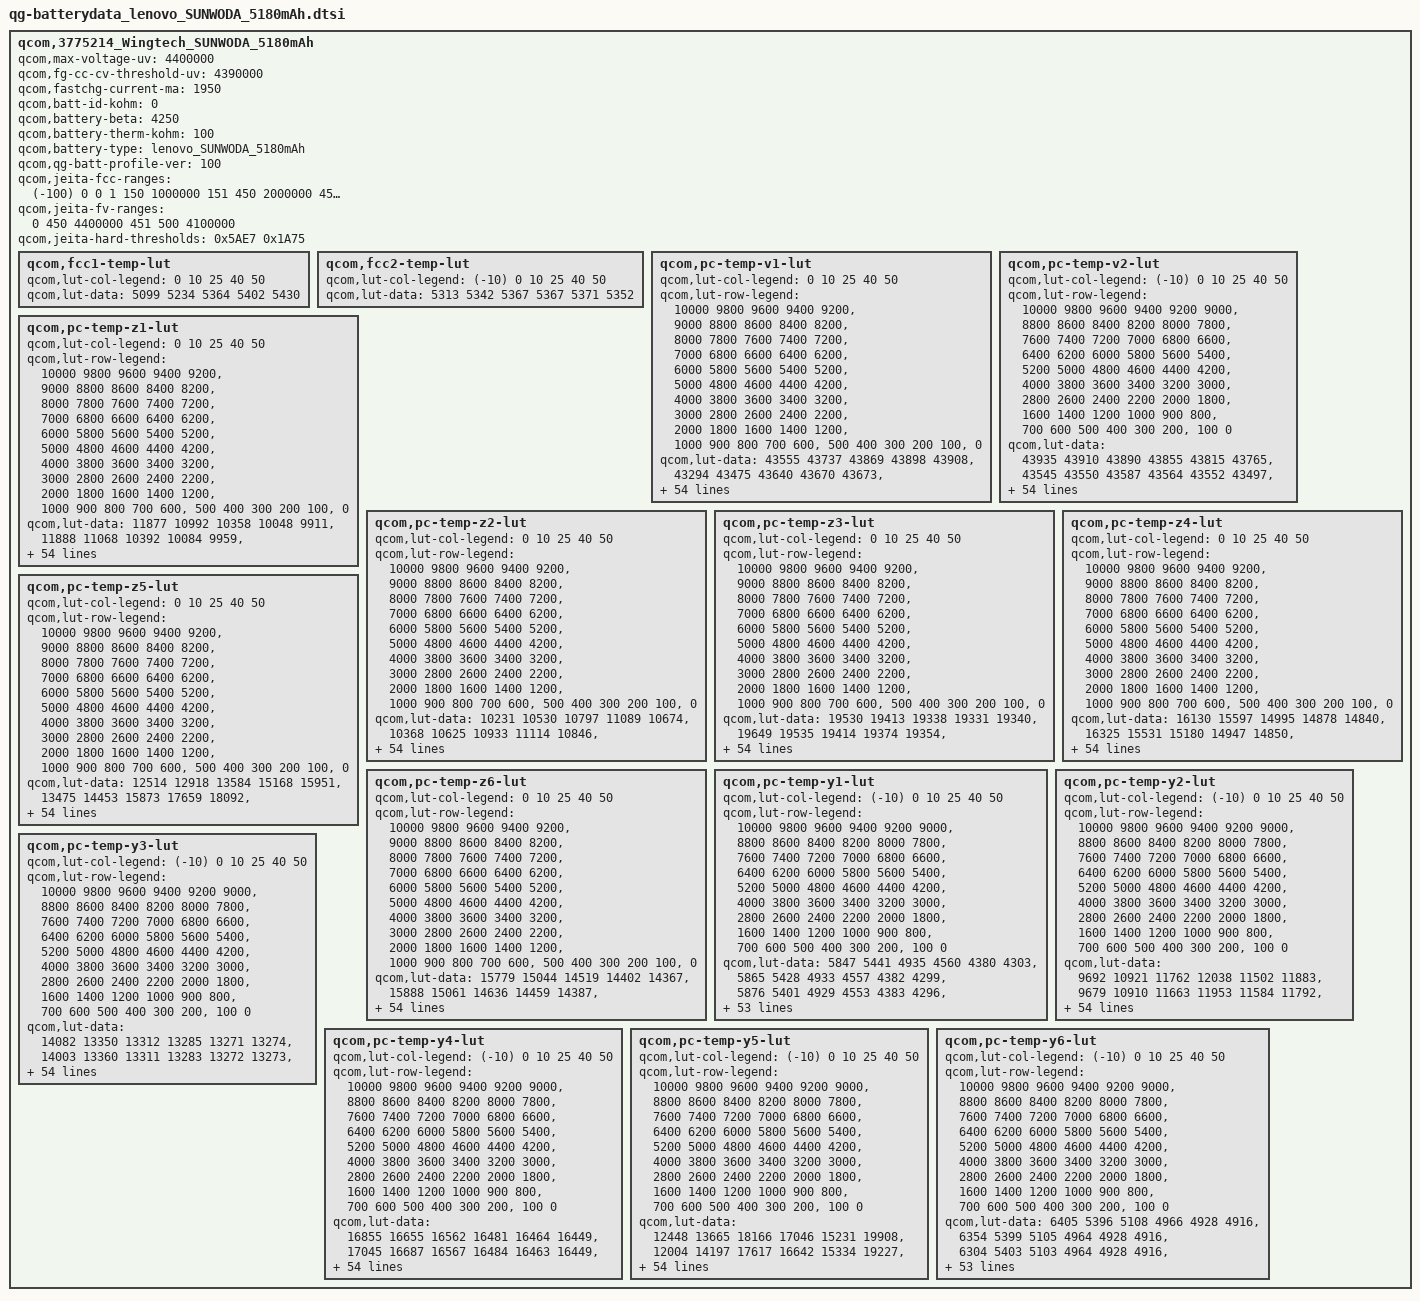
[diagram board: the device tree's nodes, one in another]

qcom,3775214_Wingtech_SUNWODA_5180mAh {
    /* 3775214_Wingtech_3677A4lenovo_5300mAh_averaged_MasterSlave_Nov30th2018 */
    qcom,max-voltage-uv = <4400000>;
    qcom,fg-cc-cv-threshold-uv = <4390000>;
    qcom,fastchg-current-ma = <1950>;
    qcom,batt-id-kohm = <0>;
    qcom,battery-beta = <4250>;
    qcom,battery-therm-kohm = <100>;
    qcom,battery-type = "lenovo_SUNWODA_5180mAh";
    qcom,qg-batt-profile-ver = <100>;
    qcom,jeita-fcc-ranges = <(-100) 0 0
                       1 150 1000000
                       151 450 2000000
		       451 500 1200000
			501 510 0>;
    qcom,jeita-fv-ranges = <0 450 4400000
                       451 500 4100000>;
    qcom,jeita-hard-thresholds = <0x5AE7 0x1A75>;

	qcom,fcc1-temp-lut {
		qcom,lut-col-legend = <0 10 25 40 50>;
		qcom,lut-data = <5099 5234 5364 5402 5430>;
	};

	qcom,fcc2-temp-lut {
		qcom,lut-col-legend = <(-10) 0 10 25 40 50>;
		qcom,lut-data = <5313 5342 5367 5367 5371 5352>;
	};

	qcom,pc-temp-v1-lut {
		qcom,lut-col-legend = <0 10 25 40 50>;
		qcom,lut-row-legend = <10000 9800 9600 9400 9200>,
			<9000 8800 8600 8400 8200>,
			<8000 7800 7600 7400 7200>,
			<7000 6800 6600 6400 6200>,
			<6000 5800 5600 5400 5200>,
			<5000 4800 4600 4400 4200>,
			<4000 3800 3600 3400 3200>,
			<3000 2800 2600 2400 2200>,
			<2000 1800 1600 1400 1200>,
			<1000 900 800 700 600>,
			<500 400 300 200 100>,
			<0>;
		qcom,lut-data = <43555 43737 43869 43898 43908>,
			<43294 43475 43640 43670 43673>,
			<43039 43220 43397 43440 43442>,
			<42791 42974 43152 43210 43214>,
			<42550 42733 42908 42974 42982>,
			<42316 42494 42663 42732 42743>,
			<42089 42260 42421 42491 42503>,
			<41872 42031 42180 42250 42263>,
			<41663 41809 41944 42011 42024>,
			<41460 41593 41711 41776 41789>,
			<41268 41390 41485 41545 41558>,
			<41070 41203 41272 41319 41331>,
			<40852 41004 41077 41097 41107>,
			<40622 40759 40870 40880 40889>,
			<40388 40494 40619 40667 40678>,
			<40130 40265 40364 40461 40474>,
			<39904 40061 40168 40267 40279>,
			<39760 39887 40011 40086 40093>,
			<39651 39756 39860 39912 39915>,
			<39541 39646 39714 39753 39749>,
			<39424 39519 39565 39597 39593>,
			<39307 39371 39381 39397 39407>,
			<39190 39211 39162 39114 39150>,
			<39071 39029 38955 38879 38913>,
			<38960 38832 38751 38750 38768>,
			<38858 38675 38582 38652 38658>,
			<38762 38546 38496 38552 38551>,
			<38673 38446 38441 38452 38446>,
			<38588 38379 38386 38361 38350>,
			<38510 38329 38325 38280 38263>,
			<38445 38287 38266 38208 38185>,
			<38385 38250 38211 38144 38116>,
			<38333 38217 38160 38089 38056>,
			<38285 38185 38112 38037 37999>,
			<38241 38158 38072 37990 37948>,
			<38199 38127 38032 37944 37899>,
			<38159 38095 37995 37897 37846>,
			<38117 38058 37956 37850 37791>,
			<38070 38003 37902 37789 37725>,
			<38015 37921 37815 37706 37642>,
			<37937 37824 37710 37607 37544>,
			<37809 37708 37600 37499 37433>,
			<37669 37572 37474 37373 37304>,
			<37522 37410 37317 37216 37150>,
			<37368 37265 37171 37069 37010>,
			<37255 37165 37078 36999 36922>,
			<37217 37142 37049 36959 36899>,
			<37185 37115 37036 36951 36881>,
			<37157 37095 37017 36929 36865>,
			<37119 37066 36989 36895 36830>,
			<36986 36926 36830 36707 36621>,
			<36584 36514 36422 36301 36205>,
			<36025 35958 35868 35750 35647>,
			<35268 35199 35109 34975 34886>,
			<34081 34021 33942 33802 33719>,
			<30000 30000 30000 30000 30000>;
	};

	qcom,pc-temp-v2-lut {
		qcom,lut-col-legend = <(-10) 0 10 25 40 50>;
		qcom,lut-row-legend = <10000 9800 9600 9400 9200 9000>,
			<8800 8600 8400 8200 8000 7800>,
			<7600 7400 7200 7000 6800 6600>,
			<6400 6200 6000 5800 5600 5400>,
			<5200 5000 4800 4600 4400 4200>,
			<4000 3800 3600 3400 3200 3000>,
			<2800 2600 2400 2200 2000 1800>,
			<1600 1400 1200 1000 900 800>,
			<700 600 500 400 300 200>,
			<100 0>;
		qcom,lut-data = <43935 43910 43890 43855 43815 43765>,
			<43545 43550 43587 43564 43552 43497>,
			<43184 43219 43300 43288 43295 43238>,
			<42851 42924 43028 43027 43047 42987>,
			<42539 42660 42772 42782 42805 42746>,
			<42269 42406 42524 42541 42566 42507>,
			<42060 42153 42280 42301 42326 42269>,
			<41871 41908 42042 42063 42088 42031>,
			<41631 41664 41811 41829 41854 41798>,
			<41327 41417 41584 41598 41623 41566>,
			<41108 41206 41363 41371 41395 41339>,
			<41027 41058 41158 41148 41171 41116>,
			<40961 40913 40946 40930 40951 40898>,
			<40735 40677 40666 40724 40739 40688>,
			<40120 40321 40316 40525 40532 40482>,
			<39638 40008 40022 40320 40332 40285>,
			<39458 39778 39789 40096 40136 40094>,
			<39326 39578 39576 39882 39948 39910>,
			<39165 39389 39364 39720 39773 39738>,
			<38985 39213 39160 39586 39608 39577>,
			<38814 39041 39029 39419 39422 39396>,
			<38656 38866 38923 39175 39196 39169>,
			<38512 38700 38821 38932 38974 38943>,
			<38396 38550 38708 38753 38789 38763>,
			<38297 38411 38561 38601 38625 38607>,
			<38214 38291 38434 38473 38490 38476>,
			<38145 38184 38328 38365 38382 38366>,
			<38085 38094 38230 38269 38285 38268>,
			<38029 38028 38140 38180 38195 38178>,
			<37978 37974 38056 38099 38111 38096>,
			<37930 37928 37980 38027 38037 38021>,
			<37883 37890 37909 37958 37967 37953>,
			<37838 37854 37850 37896 37907 37890>,
			<37790 37818 37807 37836 37860 37831>,
			<37742 37781 37772 37781 37816 37775>,
			<37690 37741 37736 37729 37752 37701>,
			<37634 37698 37703 37681 37650 37593>,
			<37574 37650 37664 37630 37551 37484>,
			<37510 37591 37614 37565 37472 37400>,
			<37442 37524 37552 37494 37398 37325>,
			<37372 37445 37477 37431 37319 37244>,
			<37298 37347 37381 37370 37234 37157>,
			<37221 37235 37261 37251 37137 37053>,
			<37138 37107 37119 37081 37014 36925>,
			<37048 36987 36989 36999 36856 36796>,
			<36948 36890 36898 36886 36817 36764>,
			<36890 36843 36878 36873 36808 36750>,
			<36828 36798 36857 36856 36792 36734>,
			<36750 36758 36810 36830 36771 36710>,
			<36631 36671 36757 36777 36726 36656>,
			<36456 36515 36568 36589 36541 36397>,
			<36110 36171 36166 36123 36037 35972>,
			<35579 35610 35572 35515 35463 35337>,
			<34781 34805 34747 34679 34648 34476>,
			<33550 33541 33509 33448 33304 33171>,
			<28789 28553 28733 29045 29438 29953>;
	};

	qcom,pc-temp-z1-lut {
		qcom,lut-col-legend = <0 10 25 40 50>;
		qcom,lut-row-legend = <10000 9800 9600 9400 9200>,
			<9000 8800 8600 8400 8200>,
			<8000 7800 7600 7400 7200>,
			<7000 6800 6600 6400 6200>,
			<6000 5800 5600 5400 5200>,
			<5000 4800 4600 4400 4200>,
			<4000 3800 3600 3400 3200>,
			<3000 2800 2600 2400 2200>,
			<2000 1800 1600 1400 1200>,
			<1000 900 800 700 600>,
			<500 400 300 200 100>,
			<0>;
		qcom,lut-data = <11877 10992 10358 10048 9911>,
			<11888 11068 10392 10084 9959>,
			<11908 11097 10392 10088 9959>,
			<11925 11077 10391 10091 9959>,
			<11937 11049 10388 10091 9959>,
			<11956 11047 10385 10089 9959>,
			<11963 11057 10383 10087 9958>,
			<11953 11064 10377 10084 9956>,
			<11937 11057 10373 10081 9954>,
			<11923 11048 10373 10081 9953>,
			<11901 11045 10374 10081 9955>,
			<11883 11044 10375 10081 9956>,
			<11877 11043 10382 10081 9956>,
			<11876 11035 10387 10080 9956>,
			<11873 11021 10376 10079 9957>,
			<11846 11019 10360 10076 9957>,
			<11821 11026 10358 10075 9958>,
			<11825 11033 10362 10077 9958>,
			<11840 11041 10366 10079 9958>,
			<11846 11053 10371 10080 9958>,
			<11840 11057 10376 10081 9959>,
			<11833 11057 10378 10082 9960>,
			<11839 11058 10379 10083 9961>,
			<11858 11057 10381 10084 9962>,
			<11873 11057 10387 10086 9964>,
			<11871 11060 10394 10090 9967>,
			<11864 11075 10396 10093 9970>,
			<11874 11090 10396 10095 9974>,
			<11916 11096 10397 10097 9976>,
			<11950 11101 10404 10101 9977>,
			<11945 11103 10413 10105 9977>,
			<11925 11099 10416 10106 9978>,
			<11917 11095 10418 10106 9980>,
			<11922 11100 10421 10107 9982>,
			<11932 11112 10425 10108 9984>,
			<11945 11123 10429 10111 9987>,
			<11965 11135 10435 10115 9988>,
			<11979 11146 10441 10122 9989>,
			<11992 11157 10446 10125 9991>,
			<12009 11170 10452 10126 9993>,
			<12005 11181 10458 10126 9996>,
			<11965 11188 10466 10127 9998>,
			<11950 11191 10473 10129 9999>,
			<11961 11192 10469 10131 10001>,
			<11936 11187 10472 10162 10003>,
			<11951 11149 10475 10153 10007>,
			<11964 11175 10476 10144 10002>,
			<11940 11151 10483 10141 10001>,
			<11944 11171 10479 10143 10005>,
			<11961 11184 10487 10146 10008>,
			<11927 11197 10486 10157 10011>,
			<11931 11187 10498 10240 10016>,
			<11946 11196 10523 10170 10022>,
			<11960 11226 10540 10179 10035>,
			<11960 11226 10540 10179 10035>,
			<11960 11226 10540 10179 10035>;
	};

	qcom,pc-temp-z2-lut {
		qcom,lut-col-legend = <0 10 25 40 50>;
		qcom,lut-row-legend = <10000 9800 9600 9400 9200>,
			<9000 8800 8600 8400 8200>,
			<8000 7800 7600 7400 7200>,
			<7000 6800 6600 6400 6200>,
			<6000 5800 5600 5400 5200>,
			<5000 4800 4600 4400 4200>,
			<4000 3800 3600 3400 3200>,
			<3000 2800 2600 2400 2200>,
			<2000 1800 1600 1400 1200>,
			<1000 900 800 700 600>,
			<500 400 300 200 100>,
			<0>;
		qcom,lut-data = <10231 10530 10797 11089 10674>,
			<10368 10625 10933 11114 10846>,
			<10428 10661 10897 11057 10978>,
			<10469 10639 10847 10967 10948>,
			<10495 10608 10781 10950 10927>,
			<10521 10610 10711 10948 10922>,
			<10530 10644 10703 10947 10916>,
			<10521 10665 10752 10962 10884>,
			<10508 10659 10799 10983 10841>,
			<10502 10646 10821 10986 10832>,
			<10491 10628 10837 10975 10845>,
			<10479 10597 10849 10968 10853>,
			<10456 10576 10863 10981 10863>,
			<10425 10575 10876 10997 10880>,
			<10403 10574 10893 11007 10869>,
			<10388 10576 10913 11016 10818>,
			<10376 10593 10928 11003 10793>,
			<10362 10619 10940 10963 10823>,
			<10347 10673 10958 10935 10858>,
			<10340 10751 11002 10944 10864>,
			<10340 10790 11058 10970 10862>,
			<10340 10808 11104 11011 10871>,
			<10340 10819 11147 11118 10935>,
			<10341 10831 11162 11190 10994>,
			<10342 10845 11091 11119 11012>,
			<10346 10848 11008 11000 11026>,
			<10353 10844 11012 11001 11021>,
			<10364 10839 11047 11120 10959>,
			<10384 10849 11077 11188 10907>,
			<10410 10878 11117 11112 10857>,
			<10436 10900 11150 11002 10787>,
			<10467 10911 11131 10961 10773>,
			<10497 10922 11074 10931 10768>,
			<10529 10935 11054 10929 10774>,
			<10562 10950 11071 11006 10794>,
			<10603 10965 11099 11113 10824>,
			<10654 10980 11136 11188 10867>,
			<10681 10996 11186 11255 10936>,
			<10486 11021 11226 11300 11003>,
			<10155 11057 11262 11369 11084>,
			<10104 11089 11289 11422 11151>,
			<10385 11115 11303 11390 11197>,
			<10423 11141 11316 11331 11254>,
			<9752 11169 11343 11331 11163>,
			<10006 11372 11384 11362 11073>,
			<10123 11570 11414 11891 11046>,
			<10193 12030 11442 11340 11090>,
			<10176 12151 11571 11924 11131>,
			<10563 12213 11676 11308 11176>,
			<10690 12427 11674 11403 11373>,
			<10414 12160 11870 11472 11152>,
			<11068 12001 11782 11338 10814>,
			<9981 12127 11760 12438 10707>,
			<9827 11598 11690 11139 10689>,
			<9827 11598 11690 11139 10689>,
			<9827 11598 11690 11139 10689>;
	};

	qcom,pc-temp-z3-lut {
		qcom,lut-col-legend = <0 10 25 40 50>;
		qcom,lut-row-legend = <10000 9800 9600 9400 9200>,
			<9000 8800 8600 8400 8200>,
			<8000 7800 7600 7400 7200>,
			<7000 6800 6600 6400 6200>,
			<6000 5800 5600 5400 5200>,
			<5000 4800 4600 4400 4200>,
			<4000 3800 3600 3400 3200>,
			<3000 2800 2600 2400 2200>,
			<2000 1800 1600 1400 1200>,
			<1000 900 800 700 600>,
			<500 400 300 200 100>,
			<0>;
		qcom,lut-data = <19530 19413 19338 19331 19340>,
			<19649 19535 19414 19374 19354>,
			<19695 19594 19456 19398 19383>,
			<19717 19606 19478 19410 19395>,
			<19712 19612 19481 19411 19397>,
			<19696 19609 19482 19404 19390>,
			<19687 19594 19480 19398 19383>,
			<19687 19578 19465 19393 19379>,
			<19687 19568 19449 19388 19375>,
			<19686 19559 19440 19383 19370>,
			<19684 19553 19432 19375 19363>,
			<19684 19547 19427 19370 19358>,
			<19692 19545 19423 19368 19355>,
			<19704 19548 19421 19366 19352>,
			<19707 19554 19421 19363 19348>,
			<19706 19552 19422 19358 19343>,
			<19704 19531 19417 19355 19339>,
			<19694 19506 19400 19351 19336>,
			<19669 19488 19390 19347 19334>,
			<19655 19474 19387 19343 19331>,
			<19651 19471 19386 19338 19327>,
			<19649 19482 19391 19338 19326>,
			<19650 19496 19411 19352 19331>,
			<19654 19509 19420 19362 19336>,
			<19657 19522 19416 19349 19331>,
			<19655 19525 19409 19328 19321>,
			<19651 19524 19401 19330 19322>,
			<19649 19523 19392 19362 19349>,
			<19651 19521 19388 19381 19370>,
			<19650 19518 19395 19381 19369>,
			<19643 19515 19403 19380 19365>,
			<19632 19511 19409 19378 19361>,
			<19622 19507 19414 19370 19354>,
			<19613 19501 19415 19364 19348>,
			<19604 19494 19411 19359 19342>,
			<19597 19488 19406 19354 19337>,
			<19591 19482 19401 19350 19333>,
			<19579 19476 19394 19346 19329>,
			<19499 19473 19391 19344 19327>,
			<19379 19471 19390 19343 19325>,
			<19354 19468 19389 19342 19325>,
			<19403 19460 19386 19340 19326>,
			<19409 19453 19383 19338 19330>,
			<19287 19448 19379 19338 19329>,
			<19264 19423 19372 19334 19326>,
			<19263 19395 19357 19301 19321>,
			<19262 19328 19358 19324 19314>,
			<19262 19324 19326 19296 19310>,
			<19260 19288 19327 19311 19307>,
			<19260 19285 19330 19309 19296>,
			<19262 19292 19315 19315 19311>,
			<19263 19293 19319 19311 19324>,
			<19263 19299 19313 19290 19322>,
			<19265 19297 19313 19310 19317>,
			<19265 19297 19313 19310 19317>,
			<19265 19297 19313 19310 19317>;
	};

	qcom,pc-temp-z4-lut {
		qcom,lut-col-legend = <0 10 25 40 50>;
		qcom,lut-row-legend = <10000 9800 9600 9400 9200>,
			<9000 8800 8600 8400 8200>,
			<8000 7800 7600 7400 7200>,
			<7000 6800 6600 6400 6200>,
			<6000 5800 5600 5400 5200>,
			<5000 4800 4600 4400 4200>,
			<4000 3800 3600 3400 3200>,
			<3000 2800 2600 2400 2200>,
			<2000 1800 1600 1400 1200>,
			<1000 900 800 700 600>,
			<500 400 300 200 100>,
			<0>;
		qcom,lut-data = <16130 15597 14995 14878 14840>,
			<16325 15531 15180 14947 14850>,
			<16183 15444 15080 14910 14856>,
			<15987 15317 14968 14840 14801>,
			<15828 15181 14900 14798 14766>,
			<15669 15093 14845 14767 14746>,
			<15534 15031 14812 14748 14733>,
			<15424 14978 14790 14739 14726>,
			<15328 14925 14775 14732 14722>,
			<15248 14879 14766 14726 14717>,
			<15179 14848 14759 14721 14712>,
			<15121 14825 14750 14715 14707>,
			<15067 14809 14739 14708 14701>,
			<15021 14801 14732 14701 14694>,
			<14996 14796 14731 14696 14688>,
			<14984 14791 14730 14691 14684>,
			<14973 14786 14726 14686 14679>,
			<14956 14781 14710 14677 14673>,
			<14934 14770 14698 14671 14667>,
			<14915 14755 14691 14669 14664>,
			<14897 14743 14688 14669 14661>,
			<14881 14732 14694 14680 14665>,
			<14868 14725 14724 14758 14735>,
			<14856 14742 14760 14817 14801>,
			<14848 14785 14815 14823 14805>,
			<14845 14814 14862 14826 14803>,
			<14843 14835 14860 14817 14793>,
			<14842 14847 14837 14766 14746>,
			<14836 14840 14813 14724 14706>,
			<14830 14820 14786 14707 14693>,
			<14827 14800 14760 14696 14684>,
			<14825 14783 14739 14688 14678>,
			<14822 14767 14721 14683 14673>,
			<14816 14753 14709 14680 14671>,
			<14808 14740 14702 14677 14671>,
			<14799 14729 14697 14676 14671>,
			<14784 14719 14693 14677 14673>,
			<14776 14712 14690 14680 14679>,
			<14844 14709 14691 14685 14686>,
			<14958 14707 14700 14693 14693>,
			<14979 14706 14709 14698 14699>,
			<14907 14707 14704 14695 14694>,
			<14890 14708 14696 14689 14685>,
			<15000 14705 14697 14692 14692>,
			<14946 14696 14689 14703 14692>,
			<14922 14697 14677 14701 14675>,
			<14916 14760 14666 14668 14670>,
			<14906 14756 14685 14676 14658>,
			<14900 14791 14671 14645 14639>,
			<14896 14788 14661 14640 14638>,
			<14897 14786 14695 14663 14657>,
			<14923 14807 14709 14712 14656>,
			<14938 14809 14719 14699 14660>,
			<14959 14823 14724 14686 14666>,
			<14959 14823 14724 14686 14666>,
			<14959 14823 14724 14686 14666>;
	};

	qcom,pc-temp-z5-lut {
		qcom,lut-col-legend = <0 10 25 40 50>;
		qcom,lut-row-legend = <10000 9800 9600 9400 9200>,
			<9000 8800 8600 8400 8200>,
			<8000 7800 7600 7400 7200>,
			<7000 6800 6600 6400 6200>,
			<6000 5800 5600 5400 5200>,
			<5000 4800 4600 4400 4200>,
			<4000 3800 3600 3400 3200>,
			<3000 2800 2600 2400 2200>,
			<2000 1800 1600 1400 1200>,
			<1000 900 800 700 600>,
			<500 400 300 200 100>,
			<0>;
		qcom,lut-data = <12514 12918 13584 15168 15951>,
			<13475 14453 15873 17659 18092>,
			<14172 15518 17152 19042 20392>,
			<14806 16161 18111 19914 21934>,
			<15481 16629 18958 20699 22751>,
			<16155 16977 19657 21469 23240>,
			<16777 17220 20121 21812 23513>,
			<17390 17523 20491 21982 23629>,
			<17999 18097 20676 22116 23654>,
			<18549 18817 20669 21953 23458>,
			<19049 19383 20642 21520 22744>,
			<19581 19802 20742 21339 22295>,
			<20322 20369 21279 21798 22682>,
			<21103 22041 21957 22398 23240>,
			<21466 24178 23160 22744 23245>,
			<21677 24398 24443 22953 22847>,
			<21795 22335 24337 22936 22729>,
			<21368 20578 23003 23453 23333>,
			<20216 20406 22268 24017 24183>,
			<19630 20585 23224 24070 24743>,
			<19875 21427 25448 24190 25218>,
			<20422 25866 31575 25588 25933>,
			<21154 32143 45733 32759 27652>,
			<22473 40213 52065 37717 28939>,
			<23477 49552 45490 30636 25448>,
			<23999 52152 35896 19158 17877>,
			<24461 49795 29791 17425 16131>,
			<24735 46689 24704 19898 19079>,
			<26293 44516 23084 22724 22405>,
			<27841 42567 23548 25380 24591>,
			<27965 40926 24482 27841 26477>,
			<27575 39456 26728 29219 27890>,
			<27322 38097 30970 30462 29078>,
			<26879 36806 33961 31695 30075>,
			<26117 35570 36599 33965 31135>,
			<25524 34820 38320 36036 31939>,
			<25468 34221 38125 35833 31668>,
			<24725 33773 37397 34311 30107>,
			<20227 34199 36741 32979 28269>,
			<14130 35818 35963 30587 25590>,
			<12898 36590 34929 27944 23513>,
			<15444 33348 33329 26376 23831>,
			<16049 30394 31252 25200 24702>,
			<12262 30245 28921 24474 23613>,
			<12237 28027 28642 23339 22836>,
			<12263 23778 25500 17985 21982>,
			<12224 15268 26373 22322 19809>,
			<12216 14947 18104 16867 19851>,
			<12209 13093 18353 20951 21925>,
			<12224 13028 19405 21709 19887>,
			<12260 13319 16426 19209 19438>,
			<12269 13184 15952 17669 19601>,
			<12148 13153 14654 14129 18065>,
			<12021 12824 14286 14917 16354>,
			<12021 12824 14286 14917 16354>,
			<12021 12824 14286 14917 16354>;
	};

	qcom,pc-temp-z6-lut {
		qcom,lut-col-legend = <0 10 25 40 50>;
		qcom,lut-row-legend = <10000 9800 9600 9400 9200>,
			<9000 8800 8600 8400 8200>,
			<8000 7800 7600 7400 7200>,
			<7000 6800 6600 6400 6200>,
			<6000 5800 5600 5400 5200>,
			<5000 4800 4600 4400 4200>,
			<4000 3800 3600 3400 3200>,
			<3000 2800 2600 2400 2200>,
			<2000 1800 1600 1400 1200>,
			<1000 900 800 700 600>,
			<500 400 300 200 100>,
			<0>;
		qcom,lut-data = <15779 15044 14519 14402 14367>,
			<15888 15061 14636 14459 14387>,
			<15832 15063 14613 14452 14401>,
			<15751 15018 14583 14434 14389>,
			<15670 14942 14558 14418 14377>,
			<15577 14890 14534 14402 14365>,
			<15500 14850 14514 14390 14355>,
			<15442 14816 14495 14382 14349>,
			<15393 14786 14481 14376 14345>,
			<15348 14761 14472 14370 14340>,
			<15306 14743 14465 14364 14334>,
			<15270 14729 14459 14359 14329>,
			<15239 14720 14453 14354 14324>,
			<15212 14715 14449 14350 14320>,
			<15196 14711 14446 14345 14315>,
			<15186 14705 14443 14341 14310>,
			<15178 14693 14436 14336 14305>,
			<15166 14680 14422 14330 14301>,
			<15152 14667 14413 14325 14297>,
			<15142 14655 14410 14322 14294>,
			<15135 14652 14409 14319 14291>,
			<15130 14654 14414 14325 14292>,
			<15129 14658 14436 14366 14325>,
			<15131 14672 14458 14397 14356>,
			<15134 14699 14481 14393 14356>,
			<15135 14716 14498 14386 14351>,
			<15138 14728 14495 14380 14347>,
			<15141 14735 14480 14376 14342>,
			<15145 14732 14469 14371 14337>,
			<15148 14721 14461 14366 14332>,
			<15146 14712 14456 14360 14327>,
			<15140 14706 14451 14354 14322>,
			<15136 14699 14447 14348 14316>,
			<15135 14692 14443 14343 14311>,
			<15134 14685 14438 14339 14307>,
			<15132 14680 14434 14336 14305>,
			<15126 14675 14430 14335 14304>,
			<15120 14672 14426 14334 14304>,
			<15115 14671 14425 14335 14305>,
			<15109 14671 14430 14338 14307>,
			<15104 14672 14435 14340 14309>,
			<15100 14671 14433 14338 14309>,
			<15094 14671 14429 14335 14307>,
			<15085 14673 14427 14335 14310>,
			<15050 14663 14422 14343 14309>,
			<15045 14645 14410 14324 14299>,
			<15041 14643 14406 14321 14293>,
			<15034 14636 14399 14309 14285>,
			<15036 14640 14393 14304 14276>,
			<15036 14637 14391 14301 14269>,
			<15047 14646 14399 14315 14286>,
			<15060 14662 14411 14351 14295>,
			<15078 14669 14417 14322 14298>,
			<15111 14691 14423 14329 14300>,
			<15111 14691 14423 14329 14300>,
			<15111 14691 14423 14329 14300>;
	};

	qcom,pc-temp-y1-lut {
		qcom,lut-col-legend = <(-10) 0 10 25 40 50>;
		qcom,lut-row-legend = <10000 9800 9600 9400 9200 9000>,
			<8800 8600 8400 8200 8000 7800>,
			<7600 7400 7200 7000 6800 6600>,
			<6400 6200 6000 5800 5600 5400>,
			<5200 5000 4800 4600 4400 4200>,
			<4000 3800 3600 3400 3200 3000>,
			<2800 2600 2400 2200 2000 1800>,
			<1600 1400 1200 1000 900 800>,
			<700 600 500 400 300 200>,
			<100 0>;
		qcom,lut-data = <5847 5441 4935 4560 4380 4303>,
			<5865 5428 4933 4557 4382 4299>,
			<5876 5401 4929 4553 4383 4296>,
			<5882 5369 4925 4550 4383 4294>,
			<5884 5342 4922 4547 4382 4293>,
			<5884 5331 4920 4546 4381 4292>,
			<5879 5331 4921 4544 4376 4293>,
			<5871 5331 4921 4542 4370 4295>,
			<5877 5333 4921 4543 4369 4295>,
			<5910 5344 4921 4546 4372 4295>,
			<5931 5353 4926 4547 4373 4295>,
			<5911 5362 4978 4545 4381 4295>,
			<5882 5369 5066 4541 4392 4295>,
			<5881 5368 5164 4541 4399 4294>,
			<5900 5364 5283 4541 4404 4293>,
			<5914 5361 5328 4542 4405 4293>,
			<5910 5358 5334 4542 4388 4294>,
			<5899 5355 5341 4543 4372 4296>,
			<5897 5355 5360 4543 4375 4298>,
			<5897 5354 5401 4545 4386 4299>,
			<5896 5354 5397 4545 4388 4299>,
			<5891 5356 5152 4543 4380 4298>,
			<5886 5359 4925 4540 4372 4297>,
			<5893 5358 4917 4541 4372 4297>,
			<5917 5354 4921 4545 4373 4298>,
			<5930 5352 4923 4547 4373 4299>,
			<5919 5362 4924 4549 4373 4300>,
			<5902 5374 4925 4551 4373 4301>,
			<5897 5370 4927 4554 4375 4302>,
			<5901 5356 4930 4558 4379 4303>,
			<5904 5350 4930 4560 4382 4304>,
			<5903 5358 4927 4563 4383 4305>,
			<5906 5365 4925 4565 4385 4307>,
			<5920 5367 4929 4567 4414 4309>,
			<5947 5366 4936 4570 4460 4311>,
			<5961 5366 4938 4571 4461 4312>,
			<5961 5366 4940 4569 4419 4314>,
			<5958 5367 4940 4568 4394 4315>,
			<5945 5372 4943 4577 4396 4316>,
			<5902 5381 4947 4595 4398 4318>,
			<5874 5382 4947 4614 4398 4318>,
			<5867 5383 4944 4639 4399 4318>,
			<5869 5395 4948 4627 4414 4319>,
			<5907 5428 4962 4590 4436 4321>,
			<5884 5394 4952 4611 4405 4319>,
			<5915 5395 4965 4600 4408 4328>,
			<5942 5395 4968 4608 4405 4324>,
			<5886 5417 4967 4607 4407 4324>,
			<5950 5386 4966 4607 4413 4324>,
			<5990 5406 4962 4604 4409 4323>,
			<5948 5431 4991 4609 4407 4326>,
			<5915 5423 4996 4620 4413 4329>,
			<5972 5437 4987 4637 4428 4335>,
			<6117 5499 5015 4655 4438 4352>,
			<6117 5499 5015 4655 4438 4352>,
			<6117 5499 5015 4655 4438 4352>;
	};

	qcom,pc-temp-y2-lut {
		qcom,lut-col-legend = <(-10) 0 10 25 40 50>;
		qcom,lut-row-legend = <10000 9800 9600 9400 9200 9000>,
			<8800 8600 8400 8200 8000 7800>,
			<7600 7400 7200 7000 6800 6600>,
			<6400 6200 6000 5800 5600 5400>,
			<5200 5000 4800 4600 4400 4200>,
			<4000 3800 3600 3400 3200 3000>,
			<2800 2600 2400 2200 2000 1800>,
			<1600 1400 1200 1000 900 800>,
			<700 600 500 400 300 200>,
			<100 0>;
		qcom,lut-data = <9692 10921 11762 12038 11502 11883>,
			<9679 10910 11663 11953 11584 11792>,
			<9673 10890 11564 11869 11645 11639>,
			<9673 10869 11471 11786 11686 11471>,
			<9678 10852 11390 11707 11709 11338>,
			<9690 10846 11330 11635 11715 11287>,
			<9872 10847 11284 11551 11685 11297>,
			<10136 10849 11249 11486 11640 11312>,
			<10128 10839 11222 11491 11613 11309>,
			<9851 10798 11200 11540 11569 11286>,
			<9680 10777 11181 11564 11543 11266>,
			<9694 10959 11147 11496 11557 11283>,
			<9713 11200 11093 11415 11576 11313>,
			<9712 11210 10957 11411 11538 11318>,
			<9691 11125 10692 11431 11426 11319>,
			<9676 11082 10569 11458 11382 11305>,
			<9674 11139 10539 11519 11425 11266>,
			<9672 11226 10520 11599 11491 11232>,
			<9672 11276 10530 11685 11550 11241>,
			<9673 11312 10574 11778 11614 11292>,
			<9673 11352 10654 11816 11678 11363>,
			<9673 11409 11177 11822 11779 11506>,
			<9672 11461 11680 11827 11864 11645>,
			<9671 11441 11774 11867 11890 11687>,
			<9669 11276 11843 11945 11897 11707>,
			<9668 11079 11889 11967 11885 11737>,
			<9667 10552 11919 11945 11814 11799>,
			<9667 10041 11944 11926 11758 11855>,
			<9667 9936 11976 11981 11792 11871>,
			<9665 9891 12014 12097 11883 11876>,
			<9663 9851 12039 12127 11988 11892>,
			<9662 9811 12062 12108 12172 12047>,
			<9662 9778 12075 12080 12291 12187>,
			<9661 9754 12058 12046 12237 12088>,
			<9660 9736 12016 12006 12123 11856>,
			<9660 9720 11965 11977 12050 11793>,
			<9659 9706 11882 11955 11990 11863>,
			<9659 9694 11805 11946 11962 11921>,
			<9659 9685 11752 11943 12004 11830>,
			<9658 9678 11699 11938 12064 11639>,
			<9658 9672 11628 11927 12080 11568>,
			<9658 9667 11518 11876 12085 11614>,
			<9657 9663 11201 11849 11932 11670>,
			<9657 9660 10584 11832 11677 11717>,
			<9657 9658 11076 11917 11838 11824>,
			<9657 9658 10626 11617 11902 11692>,
			<9656 9657 10625 11689 11633 11593>,
			<9656 9656 10655 11688 11514 11272>,
			<9656 9656 10040 11664 11702 11354>,
			<9656 9655 10138 11543 11560 11466>,
			<9656 9655 9766 11415 11355 11387>,
			<9656 9655 9694 11248 11457 12853>,
			<9655 9655 9673 11247 11413 11345>,
			<9653 9655 9662 10986 11341 11067>,
			<9653 9655 9662 10986 11341 11067>,
			<9653 9655 9662 10986 11341 11067>;
	};

	qcom,pc-temp-y3-lut {
		qcom,lut-col-legend = <(-10) 0 10 25 40 50>;
		qcom,lut-row-legend = <10000 9800 9600 9400 9200 9000>,
			<8800 8600 8400 8200 8000 7800>,
			<7600 7400 7200 7000 6800 6600>,
			<6400 6200 6000 5800 5600 5400>,
			<5200 5000 4800 4600 4400 4200>,
			<4000 3800 3600 3400 3200 3000>,
			<2800 2600 2400 2200 2000 1800>,
			<1600 1400 1200 1000 900 800>,
			<700 600 500 400 300 200>,
			<100 0>;
		qcom,lut-data = <14082 13350 13312 13285 13271 13274>,
			<14003 13360 13311 13283 13272 13273>,
			<13923 13370 13312 13282 13272 13273>,
			<13849 13378 13314 13282 13273 13272>,
			<13785 13386 13316 13281 13273 13272>,
			<13738 13392 13318 13281 13274 13273>,
			<13710 13397 13321 13282 13274 13274>,
			<13687 13400 13325 13283 13275 13274>,
			<13645 13406 13328 13283 13276 13275>,
			<13575 13414 13330 13283 13279 13275>,
			<13532 13418 13333 13283 13282 13275>,
			<13526 13411 13338 13286 13283 13276>,
			<13522 13398 13347 13291 13284 13278>,
			<13506 13389 13356 13295 13289 13278>,
			<13462 13380 13368 13298 13300 13280>,
			<13434 13374 13377 13300 13304 13280>,
			<13436 13370 13380 13299 13296 13280>,
			<13441 13367 13382 13299 13287 13279>,
			<13436 13363 13388 13299 13285 13280>,
			<13415 13359 13396 13299 13284 13281>,
			<13402 13353 13394 13299 13283 13282>,
			<13400 13348 13353 13296 13283 13279>,
			<13399 13342 13314 13291 13283 13277>,
			<13405 13334 13308 13287 13280 13275>,
			<13432 13322 13304 13283 13275 13273>,
			<13447 13309 13303 13281 13273 13272>,
			<13447 13284 13302 13280 13274 13271>,
			<13447 13264 13302 13280 13274 13271>,
			<13458 13263 13301 13281 13274 13271>,
			<13505 13265 13299 13284 13274 13271>,
			<13541 13267 13298 13285 13275 13272>,
			<13557 13271 13296 13286 13275 13271>,
			<13574 13275 13294 13286 13276 13271>,
			<13606 13281 13295 13286 13273 13272>,
			<13674 13288 13297 13285 13270 13273>,
			<13732 13297 13298 13285 13269 13274>,
			<13770 13309 13301 13286 13273 13273>,
			<13808 13325 13304 13286 13275 13272>,
			<13854 13346 13305 13287 13275 13271>,
			<13914 13376 13306 13287 13274 13270>,
			<13981 13417 13308 13288 13274 13270>,
			<14058 13477 13310 13287 13275 13270>,
			<14151 13556 13310 13286 13280 13271>,
			<14277 13663 13304 13284 13288 13273>,
			<14355 13800 13315 13288 13272 13275>,
			<14362 13861 13305 13289 13274 13278>,
			<14490 13973 13317 13289 13278 13277>,
			<14514 14090 13332 13292 13277 13277>,
			<14626 14218 13334 13295 13284 13280>,
			<14756 14332 13362 13301 13286 13284>,
			<14878 14464 13387 13301 13280 13277>,
			<14961 14556 13417 13294 13279 13307>,
			<15223 14670 13497 13308 13281 13285>,
			<16005 14842 13664 13320 13288 13281>,
			<16005 14842 13664 13320 13288 13281>,
			<16005 14842 13664 13320 13288 13281>;
	};

	qcom,pc-temp-y4-lut {
		qcom,lut-col-legend = <(-10) 0 10 25 40 50>;
		qcom,lut-row-legend = <10000 9800 9600 9400 9200 9000>,
			<8800 8600 8400 8200 8000 7800>,
			<7600 7400 7200 7000 6800 6600>,
			<6400 6200 6000 5800 5600 5400>,
			<5200 5000 4800 4600 4400 4200>,
			<4000 3800 3600 3400 3200 3000>,
			<2800 2600 2400 2200 2000 1800>,
			<1600 1400 1200 1000 900 800>,
			<700 600 500 400 300 200>,
			<100 0>;
		qcom,lut-data = <16855 16655 16562 16481 16464 16449>,
			<17045 16687 16567 16484 16463 16449>,
			<17176 16721 16571 16487 16462 16449>,
			<17256 16754 16576 16491 16462 16449>,
			<17296 16782 16580 16494 16462 16450>,
			<17307 16800 16584 16497 16462 16451>,
			<17257 16811 16586 16500 16465 16452>,
			<17182 16819 16589 16504 16468 16453>,
			<17205 16816 16594 16509 16468 16455>,
			<17405 16801 16605 16517 16467 16458>,
			<17595 16793 16619 16522 16467 16462>,
			<17723 16945 16642 16525 16471 16464>,
			<17818 17145 16673 16527 16477 16467>,
			<17728 17142 16717 16534 16474 16469>,
			<17239 17012 16782 16547 16457 16474>,
			<16945 16900 16823 16561 16454 16479>,
			<16960 16826 16839 16575 16480 16487>,
			<16981 16770 16841 16591 16515 16496>,
			<16974 16744 16825 16619 16546 16510>,
			<16921 16730 16791 16657 16579 16527>,
			<16868 16711 16747 16666 16587 16533>,
			<16828 16676 16677 16598 16554 16516>,
			<16796 16643 16611 16523 16513 16491>,
			<16778 16631 16575 16497 16487 16474>,
			<16766 16624 16549 16481 16464 16458>,
			<16760 16623 16538 16477 16459 16453>,
			<16758 16643 16532 16480 16460 16455>,
			<16757 16663 16529 16483 16462 16458>,
			<16758 16663 16529 16484 16467 16462>,
			<16763 16660 16529 16485 16473 16468>,
			<16767 16659 16528 16487 16480 16476>,
			<16770 16660 16523 16494 16487 16484>,
			<16775 16663 16520 16499 16496 16492>,
			<16779 16669 16521 16501 16517 16500>,
			<16786 16679 16523 16502 16543 16509>,
			<16791 16689 16527 16501 16540 16508>,
			<16795 16700 16533 16497 16496 16480>,
			<16800 16711 16539 16493 16465 16457>,
			<16805 16721 16546 16491 16461 16457>,
			<16813 16731 16555 16489 16458 16459>,
			<16823 16733 16563 16500 16460 16462>,
			<16837 16730 16570 16532 16468 16467>,
			<16856 16727 16585 16526 16459 16469>,
			<16893 16723 16608 16499 16439 16468>,
			<16904 16729 16583 16539 16452 16439>,
			<16860 16727 16608 16488 16459 16449>,
			<16883 16747 16620 16495 16468 16466>,
			<16917 16781 16640 16512 16490 16491>,
			<16960 16839 16708 16542 16510 16516>,
			<16962 16880 16750 16576 16549 16539>,
			<16986 16913 16794 16578 16542 16477>,
			<16961 16899 16808 16546 16473 16433>,
			<16984 16874 16823 16566 16513 16456>,
			<17215 16873 16877 16622 16552 16474>,
			<17215 16873 16877 16622 16552 16474>,
			<17215 16873 16877 16622 16552 16474>;
	};

	qcom,pc-temp-y5-lut {
		qcom,lut-col-legend = <(-10) 0 10 25 40 50>;
		qcom,lut-row-legend = <10000 9800 9600 9400 9200 9000>,
			<8800 8600 8400 8200 8000 7800>,
			<7600 7400 7200 7000 6800 6600>,
			<6400 6200 6000 5800 5600 5400>,
			<5200 5000 4800 4600 4400 4200>,
			<4000 3800 3600 3400 3200 3000>,
			<2800 2600 2400 2200 2000 1800>,
			<1600 1400 1200 1000 900 800>,
			<700 600 500 400 300 200>,
			<100 0>;
		qcom,lut-data = <12448 13665 18166 17046 15231 19908>,
			<12004 14197 17617 16642 15334 19227>,
			<11798 14995 17240 16030 15370 18421>,
			<11798 15837 17007 15363 15355 17621>,
			<11971 16496 16890 14794 15302 16960>,
			<12288 16751 16861 14475 15227 16570>,
			<14429 16691 17041 14334 15004 16402>,
			<17352 16586 17253 14195 14759 16285>,
			<17151 16729 17144 13944 15035 16074>,
			<13616 17516 16766 13516 16208 15633>,
			<11439 17788 16348 13330 16787 15301>,
			<13981 16348 15829 13735 16406 15459>,
			<17713 14643 15305 14280 15853 15782>,
			<17640 15367 14991 14449 23771 15842>,
			<14286 18959 14816 14464 48836 15853>,
			<12268 20785 14890 14455 58298 15658>,
			<12543 20058 15367 14487 37616 15126>,
			<12936 19172 15956 14568 16223 14628>,
			<12987 19233 16367 14948 14604 14516>,
			<12912 19763 16792 15998 14363 14565>,
			<12819 20004 17200 17290 14551 14799>,
			<12587 19761 18558 19633 18102 16311>,
			<12300 19329 19566 21451 21447 17875>,
			<12192 18525 19047 20608 20563 18089>,
			<12115 16826 18228 18307 18145 18146>,
			<12082 15539 18004 17288 17325 18105>,
			<12018 13653 18351 16981 17572 17452>,
			<11930 12050 18705 16827 17801 16765>,
			<11931 11962 18699 17574 17621 16598>,
			<11995 11989 18456 19268 17376 16497>,
			<12032 12040 18194 20163 17593 16520>,
			<12060 12232 17488 20820 18240 16606>,
			<12112 12452 17004 21215 19004 16763>,
			<12182 12558 17407 21186 19951 17479>,
			<12308 12631 18105 21097 20887 18821>,
			<12370 12726 18357 21288 21051 19456>,
			<12336 12886 18922 22266 20622 19339>,
			<12286 13031 19219 22921 20204 19107>,
			<12271 13158 18929 22282 19733 18462>,
			<12277 13342 18675 21175 19103 17225>,
			<12283 13440 18499 20323 18725 16813>,
			<12321 13485 18051 18513 18523 16554>,
			<12343 13462 16838 17787 44118 16914>,
			<12276 13169 14827 17500 65535 18573>,
			<12463 12839 16031 20273 17914 24233>,
			<12645 12972 13527 18546 16491 21501>,
			<12742 12794 14545 17935 17432 17297>,
			<12665 12728 15542 17734 15832 15701>,
			<12608 12943 13694 16766 17087 15884>,
			<13106 12796 14705 17122 17125 16886>,
			<13352 13485 13829 16954 15891 17000>,
			<13075 13424 13242 15758 16546 65535>,
			<12470 13036 13262 17955 17011 26318>,
			<11455 12716 12956 18583 19610 17726>,
			<11455 12716 12956 18583 19610 17726>,
			<11455 12716 12956 18583 19610 17726>;
	};

	qcom,pc-temp-y6-lut {
		qcom,lut-col-legend = <(-10) 0 10 25 40 50>;
		qcom,lut-row-legend = <10000 9800 9600 9400 9200 9000>,
			<8800 8600 8400 8200 8000 7800>,
			<7600 7400 7200 7000 6800 6600>,
			<6400 6200 6000 5800 5600 5400>,
			<5200 5000 4800 4600 4400 4200>,
			<4000 3800 3600 3400 3200 3000>,
			<2800 2600 2400 2200 2000 1800>,
			<1600 1400 1200 1000 900 800>,
			<700 600 500 400 300 200>,
			<100 0>;
		qcom,lut-data = <6405 5396 5108 4966 4928 4916>,
			<6354 5399 5105 4964 4928 4916>,
			<6304 5403 5103 4964 4928 4916>,
			<6257 5408 5102 4964 4928 4916>,
			<6215 5411 5102 4964 4929 4916>,
			<6180 5413 5102 4965 4929 4917>,
			<6147 5413 5103 4966 4930 4917>,
			<6120 5412 5105 4968 4931 4918>,
			<6105 5411 5107 4970 4932 4919>,
			<6096 5408 5111 4971 4934 4920>,
			<6092 5409 5115 4974 4936 4921>,
			<6105 5440 5143 4976 4939 4923>,
			<6124 5479 5191 4980 4942 4925>,
			<6086 5473 5254 4984 4945 4927>,
			<5918 5429 5345 4990 4949 4929>,
			<5818 5392 5408 4995 4951 4931>,
			<5840 5371 5440 4999 4952 4933>,
			<5872 5355 5462 5003 4954 4935>,
			<5870 5345 5482 5011 4959 4939>,
			<5836 5338 5500 5022 4970 4945>,
			<5813 5331 5486 5024 4973 4947>,
			<5807 5320 5286 5003 4962 4940>,
			<5802 5309 5096 4978 4949 4931>,
			<5809 5303 5075 4967 4938 4924>,
			<5842 5297 5067 4959 4928 4918>,
			<5860 5296 5065 4957 4926 4916>,
			<5857 5298 5064 4958 4927 4916>,
			<5852 5301 5064 4958 4928 4917>,
			<5864 5305 5065 4960 4929 4918>,
			<5918 5312 5067 4962 4931 4920>,
			<5955 5321 5067 4965 4933 4922>,
			<5967 5334 5066 4968 4936 4925>,
			<5980 5351 5066 4970 4939 4927>,
			<6009 5368 5068 4970 4948 4931>,
			<6074 5389 5074 4970 4958 4934>,
			<6124 5414 5079 4970 4957 4934>,
			<6152 5449 5084 4970 4941 4925>,
			<6179 5489 5091 4970 4931 4917>,
			<6212 5531 5099 4970 4929 4917>,
			<6255 5579 5108 4974 4929 4918>,
			<6307 5637 5119 4981 4929 4918>,
			<6369 5710 5130 4995 4932 4920>,
			<6446 5795 5144 4991 4935 4922>,
			<6567 5894 5161 4975 4938 4923>,
			<6619 6010 5180 4998 4927 4916>,
			<6627 6060 5193 4978 4930 4921>,
			<6734 6156 5224 4981 4936 4926>,
			<6748 6253 5265 4989 4942 4933>,
			<6851 6362 5311 5001 4952 4943>,
			<6960 6468 5370 5015 4965 4952>,
			<7061 6580 5430 5017 4959 4929>,
			<7111 6649 5495 5005 4938 4938>,
			<7351 6731 5623 5029 4955 4930>,
			<8087 6870 5827 5062 4972 4934>,
			<8087 6870 5827 5062 4972 4934>,
			<8087 6870 5827 5062 4972 4934>;
	};

};
